# STM32N645 register map
File version: 1.0
CPU: CM55 r0p1, little endian, no MPU, FPU, vendor SysTick, 8 interrupt priority bits
Registers are 32-bit, read-write, reset 0x0 unless marked. A register's access mark holds for its fields unless they carry their own. Offsets are from the block's base; [hi:lo] are bit positions; {n}, {i} and the like mark numbered series.

## DMA2D — Chrom-ART Accelerator controller
Base 0x48021000
Same registers: DMA2D_S 0x58021000
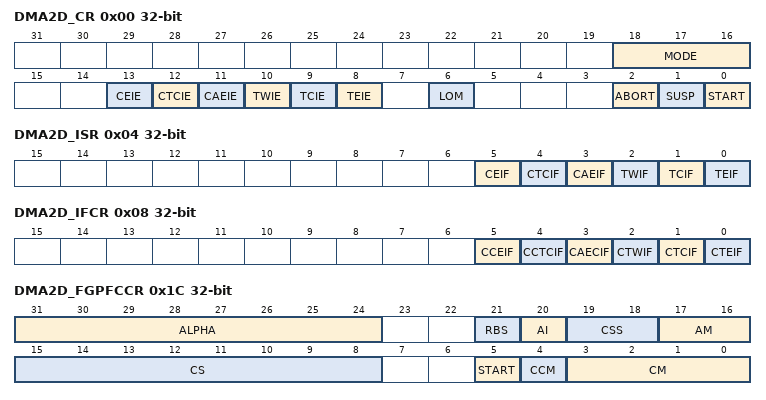
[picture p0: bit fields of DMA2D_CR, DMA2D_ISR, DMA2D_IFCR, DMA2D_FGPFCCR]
0x00 DMA2D_CR — DMA2D control register
  [18:16] MODE — DMA2D mode
    0=Memory-to-memory (FG fetch only); 1=Memory-to-memory with PFC (FG fetch only with FG PFC active); 2=Memory-to-memory with blending (FG and BG fetch with PFC and blending); 3=Register-to-memory (no FG nor BG, only output stage active); 4=Memory-to-memory with blending and fixed color FG (BG fetch only with FG and BG PFC active); 5=Memory-to-memory with blending and fixed color BG (FG fetch only with FG and BG PFC active)
  [13] CEIE — Configuration error (CE) interrupt enable
    0=CE interrupt disabled; 1=CE interrupt enabled
  [12] CTCIE — CLUT transfer complete (CTC) interrupt enable
    0=CTC interrupt disabled; 1=CTC interrupt enabled
  [11] CAEIE — CLUT access error (CAE) interrupt enable
    0=CAE interrupt disabled; 1=CAE interrupt enabled
  [10] TWIE — Transfer watermark (TW) interrupt enable
    0=TW interrupt disabled; 1=TW interrupt enabled
  [9] TCIE — Transfer complete (TC) interrupt enable
    0=TC interrupt disabled; 1=TC interrupt enabled
  [8] TEIE — Transfer error (TE) interrupt enable
    0=TE interrupt disabled; 1=TE interrupt enabled
  [6] LOM — Line offset mode
    0=Line offsets expressed in pixels; 1=Line offsets expressed in bytes
  [2] ABORT
    0=No transfer abort requested; 1=Transfer abort requested
  [1] SUSP — Suspend
    0=Transfer not suspended; 1=Transfer suspended
  [0] START
0x04 DMA2D_ISR ro — DMA2D interrupt status register
  [5] CEIF — Configuration error interrupt flag
  [4] CTCIF — CLUT transfer complete interrupt flag
  [3] CAEIF — CLUT access error interrupt flag
  [2] TWIF — Transfer watermark interrupt flag
  [1] TCIF — Transfer complete interrupt flag
  [0] TEIF — Transfer error interrupt flag
0x08 DMA2D_IFCR — DMA2D interrupt flag clear register
  [5] CCEIF — Clear configuration error interrupt flag
  [4] CCTCIF — Clear CLUT transfer complete interrupt flag
  [3] CAECIF — Clear CLUT access error interrupt flag
  [2] CTWIF — Clear transfer watermark interrupt flag
  [1] CTCIF — Clear transfer complete interrupt flag
  [0] CTEIF — Clear transfer error interrupt flag
0x0C DMA2D_FGMAR — DMA2D foreground memory address register
  [31:0] MA — Memory address, address of the data used for the foreground image
0x10 DMA2D_FGOR — DMA2D foreground offset register
  [15:0] LO — Line offset
0x14 DMA2D_BGMAR — DMA2D background memory address register
  [31:0] MA — Memory address, address of the data used for the background image
0x18 DMA2D_BGOR — DMA2D background offset register
  [15:0] LO — Line offset
0x1C DMA2D_FGPFCCR — DMA2D foreground PFC control register
  [31:24] ALPHA — Alpha value
  [21] RBS — Red/Blue swap
    0=Regular mode (RGB or ARGB); 1=Swap mode (BGR or ABGR)
  [20] AI — Alpha inverted
    0=Regular alpha; 1=Inverted alpha
  [19:18] CSS — Chroma subsampling
    0=4:4:4 (no chroma subsampling); 1=4:2:2; 2=4:2:0
  [17:16] AM — Alpha mode
    0=No modification of the foreground image alpha channel value; 1=Replace original foreground image alpha channel value by ALPHA[7: 0]; 2=Replace original foreground image alpha channel value by ALPHA[7:0] multiplied with original alpha channel value
  [15:8] CS — CLUT size
  [5] START
  [4] CCM — CLUT color mode
    0=ARGB8888; 1=RGB888
  [3:0] CM — Color mode
    0=ARGB8888; 1=RGB888; 2=RGB565; 3=ARGB1555; 4=ARGB4444; 5=L8; 6=AL44; 7=AL88; 8=L4; 9=A8; 10=A4; 11=YCbCr
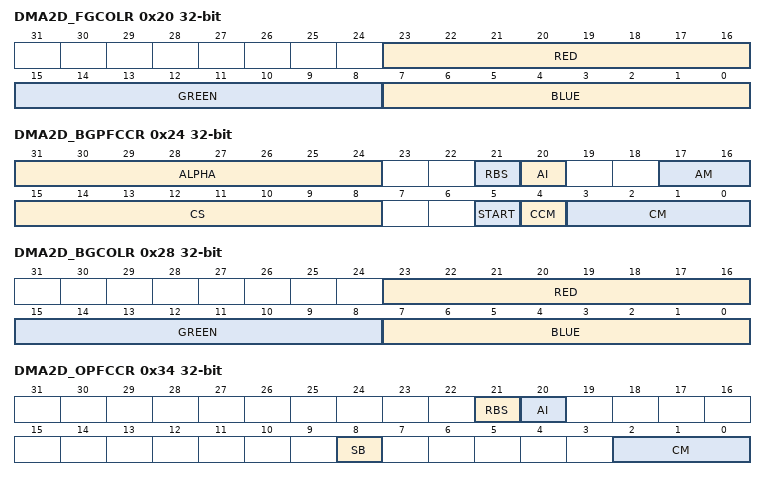
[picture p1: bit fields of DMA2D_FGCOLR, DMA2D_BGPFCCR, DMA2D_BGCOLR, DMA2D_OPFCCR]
0x20 DMA2D_FGCOLR — DMA2D foreground color register
  [23:16] RED — Red value for the A4 or A8 mode of the foreground image
  [15:8] GREEN — Green value for the A4 or A8 mode of the foreground image
  [7:0] BLUE — Blue value for the A4 or A8 mode of the foreground image
0x24 DMA2D_BGPFCCR — DMA2D background PFC control register
  [31:24] ALPHA — Alpha value
  [21] RBS — Red/Blue swap
    0=Regular mode (RGB or ARGB); 1=Swap mode (BGR or ABGR)
  [20] AI — Alpha Inverted
    0=Regular alpha; 1=Inverted alpha
  [17:16] AM — Alpha mode
    0=No modification of the foreground image alpha channel value; 1=Replace original background image alpha channel value by ALPHA[7: 0]; 2=Replace original background image alpha channel value by ALPHA[7:0] multiplied with original alpha channel value
  [15:8] CS — CLUT size
  [5] START
  [4] CCM — CLUT color mode
    0=ARGB8888; 1=RGB888
  [3:0] CM — Color mode
    0=ARGB8888; 1=RGB888; 2=RGB565; 3=ARGB1555; 4=ARGB4444; 5=L8; 6=AL44; 7=AL88; 8=L4; 9=A8; 10=A4
0x28 DMA2D_BGCOLR — DMA2D background color register
  [23:16] RED — Red value for the A4 or A8 mode of the background
  [15:8] GREEN — Green value for the A4 or A8 mode of the background
  [7:0] BLUE — Blue value for the A4 or A8 mode of the background
0x2C DMA2D_FGCMAR — DMA2D foreground CLUT memory address register
  [31:0] MA — Memory address
0x30 DMA2D_BGCMAR — DMA2D background CLUT memory address register
  [31:0] MA — Memory address
0x34 DMA2D_OPFCCR — DMA2D output PFC control register
  [21] RBS — Red/Blue swap
    0=Regular mode (RGB or ARGB); 1=Swap mode (BGR or ABGR)
  [20] AI — Alpha Inverted
    0=Regular alpha; 1=Inverted alpha
  [8] SB — Swap bytes
    0=Bytes in regular order in the output FIFO; 1=Bytes swapped two by two in the output FIFO
  [2:0] CM — Color mode
    0=ARGB8888; 1=RGB888; 2=RGB565; 3=ARGB1555; 4=ARGB4444
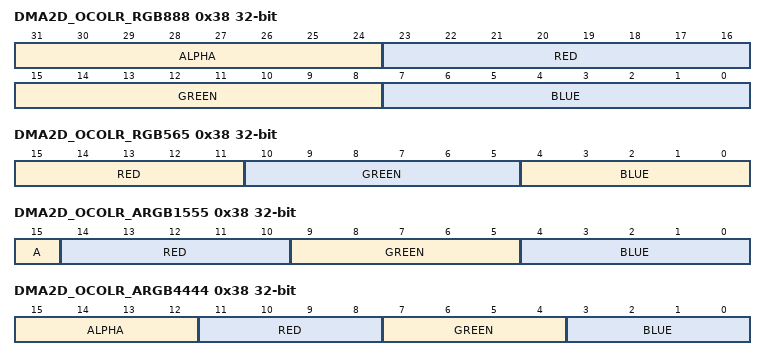
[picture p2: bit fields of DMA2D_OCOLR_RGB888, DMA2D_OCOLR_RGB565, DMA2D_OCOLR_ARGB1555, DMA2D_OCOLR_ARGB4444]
0x38 DMA2D_OCOLR_RGB888 — DMA2D output color register
  [31:24] ALPHA — Alpha channel value of the output color in ARGB8888 mode (otherwise reserved)
  [23:16] RED — Red value of the output image in ARGB8888 or RGB888 mode
  [15:8] GREEN — Green value of the output image in ARGB8888 or RGB888
  [7:0] BLUE — Blue value of the output image in ARGB8888 or RGB888
0x38 DMA2D_OCOLR_RGB565 (alternate view of DMA2D_OCOLR_RGB888) — DMA2D output color register
  [15:11] RED — Red value of the output image in RGB565 mode
  [10:5] GREEN — Green value of the output image in RGB565 mode
  [4:0] BLUE — Blue value of the output image in RGB565 mode
0x38 DMA2D_OCOLR_ARGB1555 (alternate view of DMA2D_OCOLR_RGB888) — DMA2D output color register
  [15] A — Alpha channel value of the output color in ARGB1555 mode
  [14:10] RED — Red value of the output image in ARGB1555 mode
  [9:5] GREEN — Green value of the output image in ARGB1555 mode
  [4:0] BLUE — Blue value of the output image in ARGB1555 mode
0x38 DMA2D_OCOLR_ARGB4444 (alternate view of DMA2D_OCOLR_RGB888) — DMA2D output color register
  [15:12] ALPHA — Alpha channel of the output color value in ARGB4444
  [11:8] RED — Red value of the output image in ARGB4444 mode
  [7:4] GREEN — Green value of the output image in ARGB4444 mode
  [3:0] BLUE — Blue value of the output image in ARGB4444 mode
0x3C DMA2D_OMAR — DMA2D output memory address register
  [31:0] MA — Memory address
0x40 DMA2D_OOR — DMA2D output offset register
  [15:0] LO — Line offset
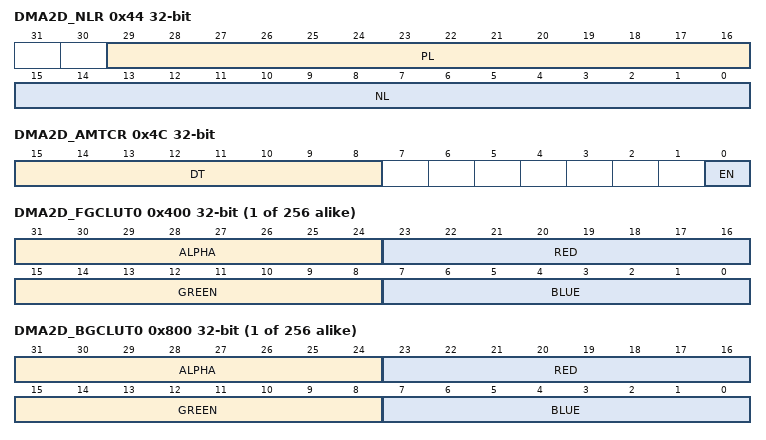
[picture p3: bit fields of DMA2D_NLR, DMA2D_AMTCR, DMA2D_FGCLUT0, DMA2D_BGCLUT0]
0x44 DMA2D_NLR — DMA2D number of line register
  [29:16] PL — Pixel per lines per lines of the area to be transferred
  [15:0] NL — Number of lines of the area to be transferred.
0x48 DMA2D_LWR — DMA2D line watermark register
  [15:0] LW — Line watermark for interrupt generation
0x4C DMA2D_AMTCR — DMA2D AXI master timer configuration register
  [15:8] DT — Dead time
  [0] EN — Dead-time functionality enable
{0x400+4i} DMA2D_FGCLUT{i} reset not defined (i=0..255) — DMA2D foreground CLUT
  [31:24] ALPHA, [23:16] RED, [15:8] GREEN, [7:0] BLUE
{0x800+4i} DMA2D_BGCLUT{i} reset not defined (i=0..255) — DMA2D background CLUT
  [31:24] ALPHA, [23:16] RED, [15:8] GREEN, [7:0] BLUE
